VERSION ""

NS_ :

BS_:

BU_:

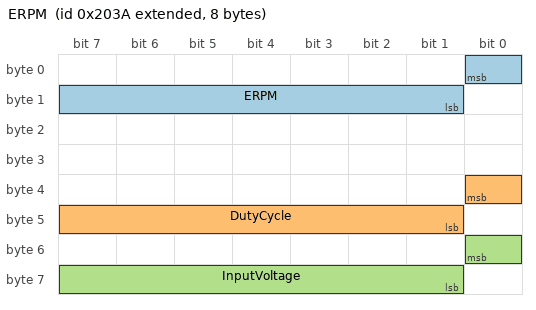
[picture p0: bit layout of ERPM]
BO_ 2147491898 ERPM: 8 Vector__XXX
	SG_ ERPM : 0|8@0+ (1,0) [-2147483648|2147483647] "ERPM" Vector__XXX
	SG_ DutyCycle : 32|8@0+ (10,0) [-3276.8|3276.7] "%" Vector__XXX
	SG_ InputVoltage : 48|8@0+ (1,0) [-32768|32767] "V" Vector__XXX

CM_ BO_ 2147491898 "ERPM, Duty, Input Voltage";
CM_ SG_ 2147483680 ERPM "Electrical RPM Equation: ERPM = Motor RPM * number of the motor pole pairs.";
BA_DEF_ SG_  "SPN" INT 0 524287;
BA_DEF_ BO_  "VFrameFormat" ENUM  "StandardCAN","ExtendedCAN","reserved","J1939PG";
BA_DEF_  "DatabaseVersion" STRING ;
BA_DEF_  "BusType" STRING ;
BA_DEF_  "ProtocolType" STRING ;
BA_DEF_  "DatabaseCompiler" STRING ;
BA_DEF_DEF_  "SPN" 0;
BA_DEF_DEF_  "VFrameFormat" "J1939PG";
BA_DEF_DEF_  "DatabaseVersion" "DEMO PLUS";
BA_DEF_DEF_  "BusType" "";
BA_DEF_DEF_  "ProtocolType" "";
BA_DEF_DEF_  "DatabaseCompiler" "";
BA_ "ProtocolType" "J1939";
BA_ "BusType" "CAN";
BA_ "DatabaseCompiler" "CSS ELECTRONICS (WWW.CSSELECTRONICS.COM)";
BA_ "DatabaseVersion" "1.0.0";
BA_ "SPN" SG_ 2364540158 EngineSpeed 190;
